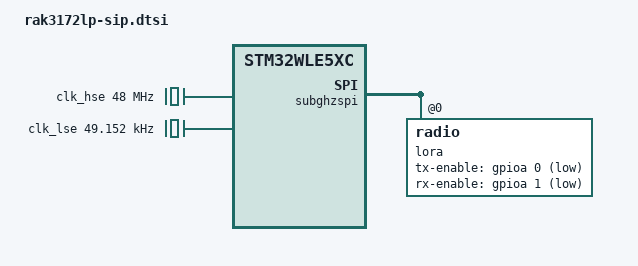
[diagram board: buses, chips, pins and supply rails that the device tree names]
/*
 * Copyright (c) 2024 Benjamin Cabé <benjamin@zephyrproject.org>
 *
 * SPDX-License-Identifier: Apache-2.0
 */

#include <st/wl/stm32wle5Xc.dtsi>
#include <st/wl/stm32wle5jcix-pinctrl.dtsi>

&clk_hse {
	clock-frequency = <DT_FREQ_M(48)>;
};

&clk_lse {
	clock-frequency = <49152>;
};

&subghzspi {
	status = "okay";
	lora: radio@0 {
		status = "okay";
		tx-enable-gpios = <&gpioa 0 GPIO_ACTIVE_LOW>;
		rx-enable-gpios = <&gpioa 1 GPIO_ACTIVE_LOW>;
		dio3-tcxo-voltage = <SX126X_DIO3_TCXO_3V0>;
		tcxo-power-startup-delay-ms = <5>;
		power-amplifier-output = "rfo-lp";
		// rfo-lp-max-power = <10>;
		rfo-hp-max-power = <14>;
	};
};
